# PHY6222 register map
File version: 1.0
PhyPlus PHY6222
CPU: CM0 r0p0, little endian, no MPU, no FPU, 2 interrupt priority bits
Registers are 32-bit, read-write, reset 0x0 unless marked. A register's access mark holds for its fields unless they carry their own. Offsets are from the block's base; lines under a group give offsets from that group; [hi:lo] are bit positions; {n}, {i} and the like mark numbered series; 'fields as' and 'values as' point back to an identical list; <NAME> marks a mode.

## Memory map
0x40001000 TIM1 size 0xA0 — Timer
0x40001014 TIM2 size 0xA0
0x40001028 TIM3 size 0xA0
0x4000103C TIM4 size 0xA0
0x40001050 TIM5 size 0xA0
0x40001064 TIM6 size 0xA0
0x400010A0 TIM_SYS size 0x80 — SysTick
0x40003800 IOMUX size 0x2A0
0x4000F000 AON size 0x2A0
0x48008000 GPIO size 0x3C0 — General-purpose I/Os

## Interrupts
-1 SysTick_IRQn (TIM_SYS) — SysTick interrupt
20 TIM1_IRQn (TIM1) — TIM1 interrupt

## TIM1 — Timer
Base 0x40001000
Same registers: TIM2 0x40001014, TIM3 0x40001028, TIM4 0x4000103C, TIM5 0x40001050, TIM6 0x40001064
0x00 LoadCount
0x04 CurrentCount
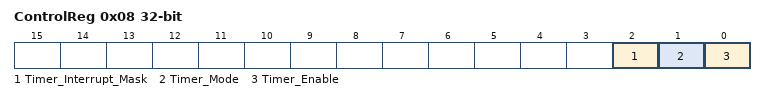
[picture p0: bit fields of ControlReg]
0x08 ControlReg
  [2] Timer_Interrupt_Mask — Interrup Mask
  [1] Timer_Mode
  [0] Timer_Enable
0x0C EOI
  [0] Timer_End_of_Interrupt
0x10 status
  [0] Timer_Interrupt_Status — Interrupt status

## TIM_SYS — SysTick
Base 0x400010A0
0x00 IntStatus
0x04 EOI
0x08 unMaskIntStatus
0x0C version

## IOMUX
Base 0x40003800
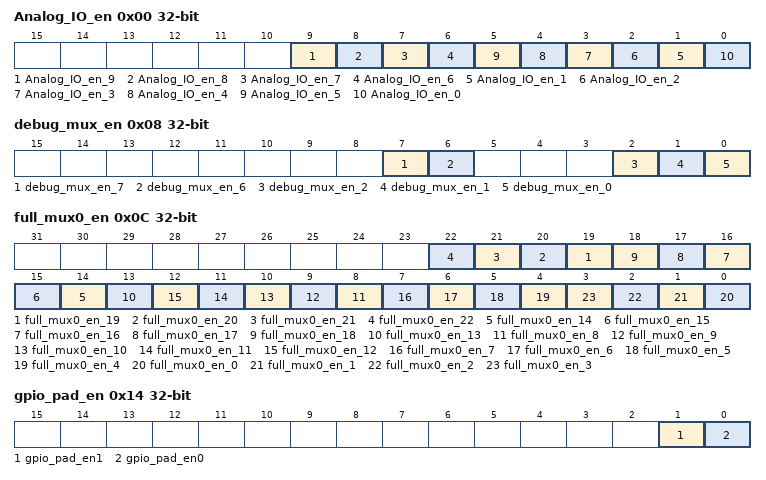
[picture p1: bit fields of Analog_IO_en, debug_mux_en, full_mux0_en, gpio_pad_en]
0x00 Analog_IO_en — Pin configuration as Analog input
  [9] Analog_IO_en_9 — AIO_8
  [8] Analog_IO_en_8 — AIO_2
  [7] Analog_IO_en_7 — AIO_1
  [6] Analog_IO_en_6 — AIO_9
  [n] Analog_IO_en_{n} (n=1..5) — AIO_{n+2}
  [0] Analog_IO_en_0 — AIO_0
0x04 SPI_debug_en
0x08 debug_mux_en
  [7] debug_mux_en_7 — Clock XT 32.768kHz
  [6] debug_mux_en_6 — Clock RC 32.768kHz
  [2] debug_mux_en_2 — Clock 1.28MHz
  [1] debug_mux_en_1 — Clock PCLK/4
  [0] debug_mux_en_0 — Clock HCLK/8
0x0C full_mux0_en — Pin routing to the full mux
  [n] full_mux0_en_{n} (n=19..22) — GPIO{n+12} routing enable
  [n] full_mux0_en_{n} (n=14..18) — GPIO{n+9} routing enable
  [13] full_mux0_en_13 — GPIO20 routing enable
  [n] full_mux0_en_{n} (n=8..12) — GPIO{n+6} routing enable
  [7] full_mux0_en_7 — GPIO11 routing enable
  [6] full_mux0_en_6 — GPIO10 routing enable
  [5] full_mux0_en_5 — GPIO09 routing enable
  [4] full_mux0_en_4 — GPIO07 routing enable
  [n] full_mux0_en_{n} (n=0..3) — GPIO{n:02} routing enable
0x10 full_mux1_en — Pin routing to the full mux (reserved)
0x14 gpio_pad_en — SWD pin routing
  [1] gpio_pad_en1 — GPIO03 selection as GPIO03 or SWD_CLK
  [0] gpio_pad_en0 — GPIO02 selection as GPIO03 or SWD_IO
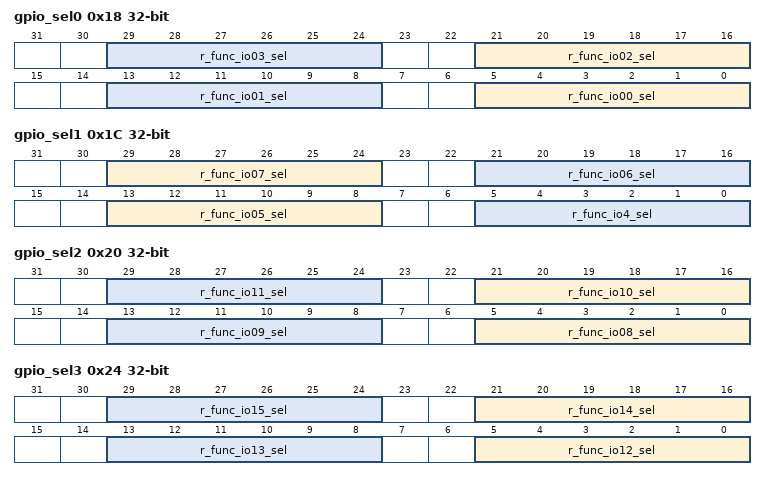
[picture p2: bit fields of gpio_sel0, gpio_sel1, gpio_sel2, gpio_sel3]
0x18 gpio_sel0 — GPIO function selection register 0
  [8n+5:8n] r_func_io{n:02}_sel (n=0..3) — GPIO{n:02} function selection
0x1C gpio_sel1 — GPIO function selection register 1
  [29:24] r_func_io07_sel — GPIO07 function selection
  [21:16] r_func_io06_sel — GPIO06 function selection
  [13:8] r_func_io05_sel — GPIO05 function selection
  [5:0] r_func_io4_sel — GPIO04 function selection
0x20 gpio_sel2 — GPIO function selection register 2
  [8n-59:8n-64] r_func_io{n:02}_sel (n=8..11) — GPIO{n:02} function selection
0x24 gpio_sel3 — GPIO function selection register 3
  [8n-91:8n-96] r_func_io{n}_sel (n=12..15) — GPIO{n} function selection
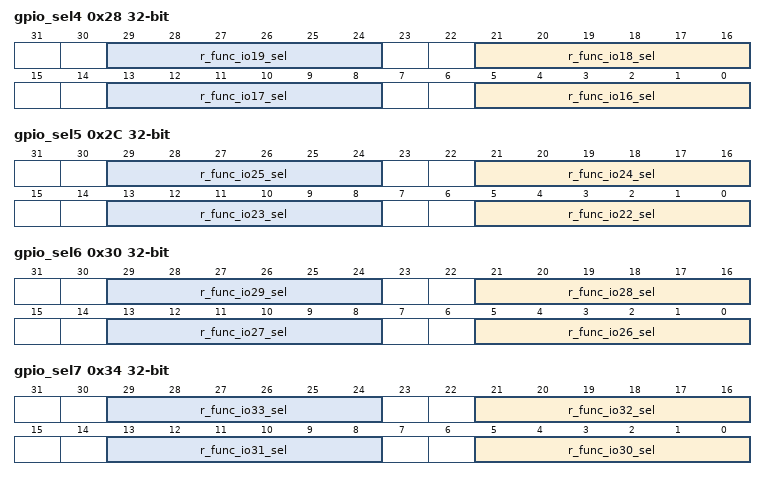
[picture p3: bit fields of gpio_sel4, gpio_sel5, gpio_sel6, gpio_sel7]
0x28 gpio_sel4 — GPIO function selection register 4
  [8n-123:8n-128] r_func_io{n}_sel (n=16..19) — GPIO{n} function selection
0x2C gpio_sel5 — GPIO function selection register 5
  [8n-171:8n-176] r_func_io{n}_sel (n=22..25) — GPIO{n} function selection
0x30 gpio_sel6 — GPIO function selection register 6
  [8n-203:8n-208] r_func_io{n}_sel (n=26..29) — GPIO{n} function selection
0x34 gpio_sel7 — GPIO function selection register 74
  [8n-235:8n-240] r_func_io{n}_sel (n=30..33) — GPIO{n} function selection
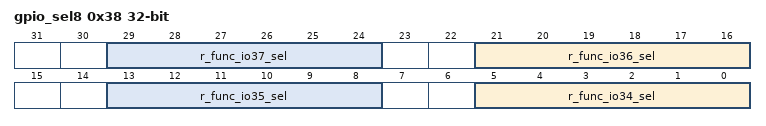
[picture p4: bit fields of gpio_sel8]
0x38 gpio_sel8 — GPIO function selection register 8
  [8n-267:8n-272] r_func_io{n}_sel (n=34..37) — GPIO{n} function selection
0x3C pad_pe0 — GPIO PAD PE0
  [20] r_io_pe
0x40 pad_pe1 — GPIO PAD PE1
0x44 pad_ps0 — GPIO PAD PS0
  [20] r_io_ds — GPIO PAD DS0
0x48 pad_ps1 — GPIO PAD PS1
0x4C keyscan_in_en — GPIO KeyScan in
0x50 keyscan_out_en — GPIO KeyScan out
